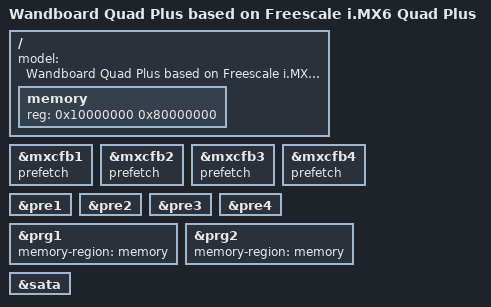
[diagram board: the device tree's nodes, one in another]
/*
 * Copyright 2015 wandboard.org.
 *
 * Author: Richard Hu <hakahu@gmail.com>
 *
 * The code contained herein is licensed under the GNU General Public
 * License. You may obtain a copy of the GNU General Public License
 * Version 2 or later at the following locations:
 *
 * http://www.opensource.org/licenses/gpl-license.html
 * http://www.gnu.org/copyleft/gpl.html
 */

#include "imx6q-wandboard.dts"
#include "imx6qp.dtsi"

/ {
	model = "Wandboard Quad Plus based on Freescale i.MX6 Quad Plus";

	memory: memory {
		reg = <0x10000000 0x80000000>;
	};
};

&mxcfb1 {
	prefetch;
};

&mxcfb2 {
	prefetch;
};

&mxcfb3 {
	prefetch;
};

&mxcfb4 {
	prefetch;
};

&pre1 {
	status = "okay";
};

&pre2 {
	status = "okay";
};

&pre3 {
	status = "okay";
};

&pre4 {
	status = "okay";
};

&prg1 {
	memory-region = <&memory>;
	status = "okay";
};

&prg2 {
	memory-region = <&memory>;
	status = "okay";
};

&sata {
	status = "okay";
};
